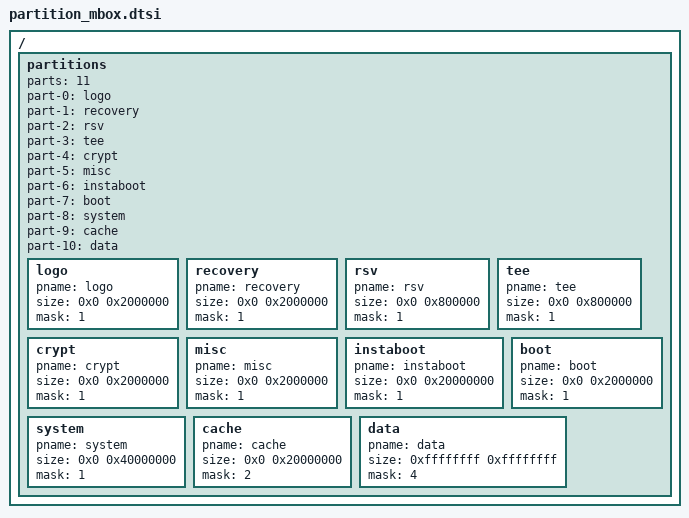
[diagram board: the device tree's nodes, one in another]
/*
 * Amlogic partition set for normal
 *
 * Copyright (c) 2017-2017 Amlogic Ltd
 *
 * This file is licensed under a dual GPLv2 or BSD license.
 *
 */
 / {
	partitions: partitions{
        parts = <11>;
		part-0 = <&logo>;
		part-1 = <&recovery>;
		part-2 = <&rsv>;
		part-3 = <&tee>;
		part-4 = <&crypt>;
		part-5 = <&misc>;
		part-6 = <&instaboot>;
		part-7 = <&boot>;
		part-8 = <&system>;
		part-9 = <&cache>;
		part-10 = <&data>;

		logo:logo{
			pname = "logo";
			size = <0x0 0x2000000>;
			mask = <1>;
		};
		recovery:recovery{
			pname = "recovery";
			size = <0x0 0x2000000>;
			mask = <1>;
		};
		rsv:rsv{
			pname = "rsv";
			size = <0x0 0x800000>;
			mask = <1>;
		};
		tee:tee{
			pname = "tee";
			size = <0x0 0x800000>;
			mask = <1>;
		};
		crypt:crypt{
			pname = "crypt";
			size = <0x0 0x2000000>;
			mask = <1>;
		};
		misc:misc{
			pname = "misc";
			size = <0x0 0x2000000>;
			mask = <1>;
		};
		instaboot:instaboot{
			pname = "instaboot";
			size = <0x0 0x20000000>;
			mask = <1>;
		};
		boot:boot
		{
			pname = "boot";
			size = <0x0 0x2000000>;
			mask = <1>;
		};
		system:system
		{
			pname = "system";
			size = <0x0 0x40000000>;
			mask = <1>;
		};
		cache:cache
		{
			pname = "cache";
			size = <0x0 0x20000000>;
			mask = <2>;
		};
		data:data
		{
			pname = "data";
			size = <0xffffffff 0xffffffff>;
			mask = <4>;
		};
	};
 };/* end of / */
